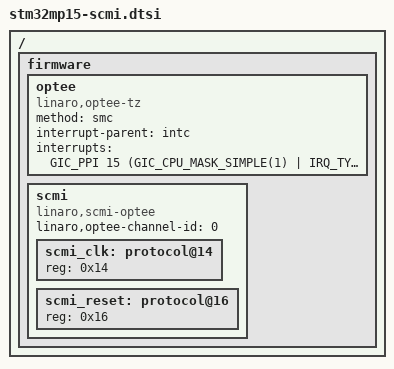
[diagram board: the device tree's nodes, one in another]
// SPDX-License-Identifier: (GPL-2.0+ OR BSD-3-Clause)
/*
 * Copyright (C) STMicroelectronics 2022 - All Rights Reserved
 * Author: Alexandre Torgue <alexandre.torgue@foss.st.com> for STMicroelectronics.
 */

/ {
	firmware {
		optee: optee {
			compatible = "linaro,optee-tz";
			method = "smc";
			interrupt-parent = <&intc>;
			interrupts = <GIC_PPI 15 (GIC_CPU_MASK_SIMPLE(1) | IRQ_TYPE_LEVEL_LOW)>;
		};

		scmi: scmi {
			compatible = "linaro,scmi-optee";
			#address-cells = <1>;
			#size-cells = <0>;
			linaro,optee-channel-id = <0>;

			scmi_clk: protocol@14 {
				reg = <0x14>;
				#clock-cells = <1>;
			};

			scmi_reset: protocol@16 {
				reg = <0x16>;
				#reset-cells = <1>;
			};
		};
	};
};

/delete-node/ &clk_hse;
/delete-node/ &clk_hsi;
/delete-node/ &clk_lse;
/delete-node/ &clk_lsi;
/delete-node/ &clk_csi;
